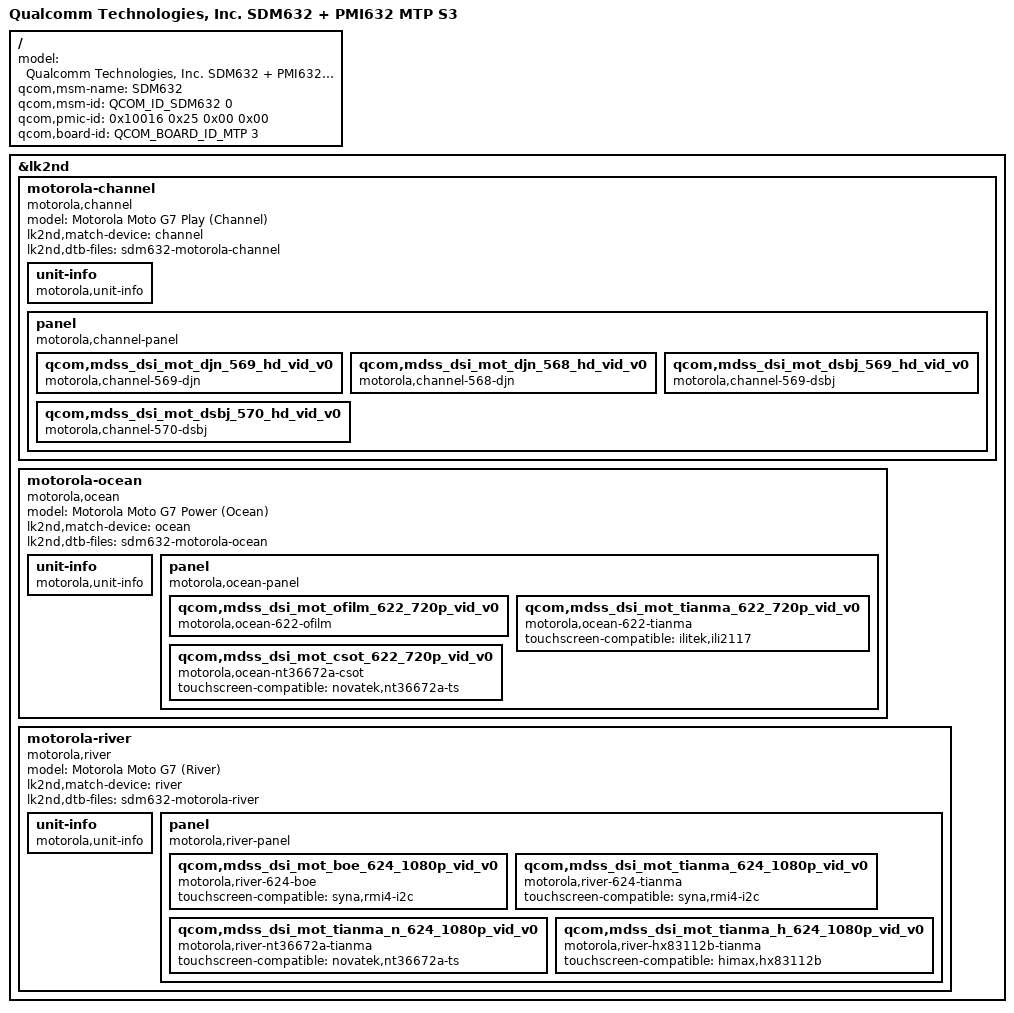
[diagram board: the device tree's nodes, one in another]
// SPDX-License-Identifier: GPL-2.0-only

/dts-v1/;

#include <skeleton64.dtsi>
#include <lk2nd.dtsi>
#include <motorola-carrier-channel-ids.dtsi>

/ {
	/* model|msm-name|pmic appears to be required by bootloader to pick dtb */

	model = "Qualcomm Technologies, Inc. SDM632 + PMI632 MTP S3";
	qcom,msm-name = "SDM632";
	qcom,msm-id = <QCOM_ID_SDM632 0>;
	qcom,pmic-id = <0x10016 0x25 0x00 0x00>;
	qcom,board-id = <QCOM_BOARD_ID_MTP 3>;
	/* Bootloader appears to really want to access symbols */
	__symbols__ {};
};

&lk2nd {
	motorola-channel {
		model = "Motorola Moto G7 Play (Channel)";
		compatible = "motorola,channel";

		lk2nd,match-device = "channel";
		lk2nd,dtb-files = "sdm632-motorola-channel";

		unit-info {
			compatible = "motorola,unit-info";
		};

		panel {
			compatible = "motorola,channel-panel", "lk2nd,panel";

			qcom,mdss_dsi_mot_djn_569_hd_vid_v0 {
				compatible = "motorola,channel-569-djn";
			};

			qcom,mdss_dsi_mot_djn_568_hd_vid_v0 {
				compatible = "motorola,channel-568-djn";
			};

			qcom,mdss_dsi_mot_dsbj_569_hd_vid_v0 {
				compatible = "motorola,channel-569-dsbj";
			};

			qcom,mdss_dsi_mot_dsbj_570_hd_vid_v0 {
				compatible = "motorola,channel-570-dsbj";
			};
		};
	};

	motorola-ocean {
		model = "Motorola Moto G7 Power (Ocean)";
		compatible = "motorola,ocean";

		lk2nd,match-device = "ocean";
		lk2nd,dtb-files = "sdm632-motorola-ocean";

		unit-info {
			compatible = "motorola,unit-info";
		};

		panel {
			compatible = "motorola,ocean-panel", "lk2nd,panel";

			qcom,mdss_dsi_mot_ofilm_622_720p_vid_v0 {
				compatible = "motorola,ocean-622-ofilm";
			};

			qcom,mdss_dsi_mot_tianma_622_720p_vid_v0 {
				compatible = "motorola,ocean-622-tianma";
				touchscreen-compatible = "ilitek,ili2117"; /* TESTED */
			};

			qcom,mdss_dsi_mot_csot_622_720p_vid_v0 {
				compatible = "motorola,ocean-nt36672a-csot";
				touchscreen-compatible = "novatek,nt36672a-ts"; /* CONFIRMED from downstream src */
			};
		};
	};

	motorola-river {
		model = "Motorola Moto G7 (River)";
		compatible = "motorola,river";

		lk2nd,match-device = "river";
		lk2nd,dtb-files = "sdm632-motorola-river";

		unit-info {
			compatible = "motorola,unit-info";
		};

		panel {
			compatible = "motorola,river-panel", "lk2nd,panel";

			qcom,mdss_dsi_mot_boe_624_1080p_vid_v0 {
				compatible = "motorola,river-624-boe";
				touchscreen-compatible = "syna,rmi4-i2c"; /* UNTESTED */
			};

			qcom,mdss_dsi_mot_tianma_624_1080p_vid_v0 {
				compatible = "motorola,river-624-tianma";
				touchscreen-compatible = "syna,rmi4-i2c"; /* UNTESTED */
			};

			qcom,mdss_dsi_mot_tianma_n_624_1080p_vid_v0 {
				compatible = "motorola,river-nt36672a-tianma";
				touchscreen-compatible = "novatek,nt36672a-ts"; /* TESTED */
			};

			qcom,mdss_dsi_mot_tianma_h_624_1080p_vid_v0 {
				compatible = "motorola,river-hx83112b-tianma";
				touchscreen-compatible = "himax,hx83112b"; /* UNTESTED */
			};
		};
	};
};
